# axil_mailbox_sep_wrap: IP-XACT component
VLNV tenstorrent.com:ocah:axil_mailbox_sep_wrap:1.0

## Address spaces and blocks
axil_mailbox_sep_wrap.outbound_mailbox_0: base 'h0, range 'h50, width 64
axil_mailbox_sep_wrap.inbound_mailbox_0: base 'h800, range 'h50, width 64
axil_mailbox_sep_wrap.outbound_mailbox_1: base 'h1000, range 'h50, width 64
axil_mailbox_sep_wrap.inbound_mailbox_1: base 'h1800, range 'h50, width 64
axil_mailbox_sep_wrap.outbound_mailbox_2: base 'h2000, range 'h50, width 64
axil_mailbox_sep_wrap.inbound_mailbox_2: base 'h2800, range 'h50, width 64
axil_mailbox_sep_wrap.outbound_mailbox_3: base 'h3000, range 'h50, width 64
axil_mailbox_sep_wrap.inbound_mailbox_3: base 'h3800, range 'h50, width 64
axil_mailbox_sep_wrap.outbound_mailbox_4: base 'h4000, range 'h50, width 64
axil_mailbox_sep_wrap.inbound_mailbox_4: base 'h4800, range 'h50, width 64
axil_mailbox_sep_wrap.outbound_mailbox_5: base 'h5000, range 'h50, width 64
axil_mailbox_sep_wrap.inbound_mailbox_5: base 'h5800, range 'h50, width 64
axil_mailbox_sep_wrap.outbound_mailbox_6: base 'h6000, range 'h50, width 64
axil_mailbox_sep_wrap.inbound_mailbox_6: base 'h6800, range 'h50, width 64
axil_mailbox_sep_wrap.outbound_mailbox_7: base 'h7000, range 'h50, width 64
axil_mailbox_sep_wrap.inbound_mailbox_7: base 'h7800, range 'h50, width 64

## Registers
Registers are 64-bit, read-only, reset 0x0 unless marked. A register's access mark holds for its fields unless they carry their own. Offsets are from the block's base; lines under a group give offsets from that group; [hi:lo] are bit positions; {n}, {i} and the like mark numbered series; 'fields as' and 'values as' point back to an identical list; <NAME> marks a mode.

## axil_mailbox_sep_wrap.outbound_mailbox_0 — Register interface for a single AXI-Lite mailbox: data FIFOs, level and status flags, and interrupt controls.
Base 0x00000000
Same registers: axil_mailbox_sep_wrap.inbound_mailbox_{n} {0x800+0x1000*n} (n=0..7), axil_mailbox_sep_wrap.outbound_mailbox_1 0x00001000, axil_mailbox_sep_wrap.outbound_mailbox_2 0x00002000, axil_mailbox_sep_wrap.outbound_mailbox_3 0x00003000, axil_mailbox_sep_wrap.outbound_mailbox_4 0x00004000, axil_mailbox_sep_wrap.outbound_mailbox_5 0x00005000, axil_mailbox_sep_wrap.outbound_mailbox_6 0x00006000, axil_mailbox_sep_wrap.outbound_mailbox_7 0x00007000
0x00 WRITE_DATA wo
  [63:0] write_data — Write data to mailbox fifo. Any write pushes one entry, irrespective of WSTRB, including a write with no byte lanes enabled; byte lanes whose strobe is 0 are pushed as 0.
0x08 READ_DATA reset not defined — A read of any size or alignment within this register pops one whole 64-bit entry from the mailbox fifo, and only the byte lanes it requests are returned. A 32-bit read of either half therefore discards the other half of the entry; read this register with 64-bit accesses. A read while the fifo is empty returns 0x0000_0000_FEED_DEAD with an error response.
  [63:0] read_data read-modifies — Read data from mailbox fifo
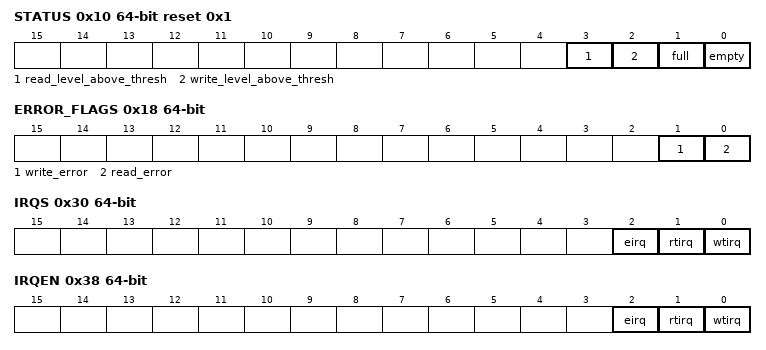
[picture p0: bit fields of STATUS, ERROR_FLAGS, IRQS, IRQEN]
0x10 STATUS reset 0x1
  [3] read_level_above_thresh — If set, read fifo level is higher than threshold set in RIRQT
  [2] write_level_above_thresh — If set, write fifo level is higher than threshold set in WIRQT
  [1] full — 0: Space is available to write, 1: Space is not available to write
  [0] empty — 0: Data is available to read, 1: Data is not available to read
0x18 ERROR_FLAGS — A read of any size or alignment within this register clears every flag in it. The flags are only returned in the lower 32 bits, so a 32-bit read of the upper half returns 0 and still clears them; read this register with 64-bit accesses or at its lower half.
  [1] write_error read-clears — Attempted write to a full mailbox
  [0] read_error read-clears — Attempted read from an empty mailbox
0x20 WIRQT rw
  [63:0] wirqt — When the usage pointer of the FIFO connected to the W channel exceeds this value, a write threshold IRQ is triggered and the corresponding STATUS register bit is set. When a value larger than or equal to the MailboxDepth parameter is written to this register, it gets reduced to MailboxDepth - 1 to ensure an IRQ is triggered when the write FIFO is full.
0x28 RIRQT rw
  [63:0] rirqt — When the fill pointer of the FIFO connected to the R channel exceeds this value, a read threshold IRQ is triggered and the corresponding STATUS register bit is set. When a value larger than or equal to the MailboxDepth parameter is written to this register, it gets reduced to MailboxDepth - 1 to ensure an IRQ is triggered when the read FIFO is full.
0x30 IRQS rw — This register is used to read and clear interrupt requests, regardless of IRQEN register and whether the interrupt is enabled or disabled.
  [2] eirq write-1-clears — On read: [0]: No interrupt request [1]: Error on mailbox access On write: [0]: No acknowledge [1]: Acknowledge and clear interrupt request
  [1] rtirq write-1-clears — On read: [0]: No interrupt request [1]: Usage level threshold in read mailbox exceeded On write: [0]: No acknowledge [1]: Acknowledge and clear interrupt request
  [0] wtirq write-1-clears — On read: [0]: No interrupt request [1]: Usage level threshold in write mailbox exceeded On write: [0]: No acknowledge [1]: Acknowledge and clear interrupt request
0x38 IRQEN rw — This register is used to enable and disable which interrupts are sent to the CPU.
  [2] eirq — [0]: Error IRQ disabled [1]: Error IRQ enabled
  [1] rtirq — [0]: Read threshold IRQ disabled [1]: Read threshold IRQ enabled
  [0] wtirq — [0]: Write threshold IRQ disabled [1]: Write threshold IRQ enabled
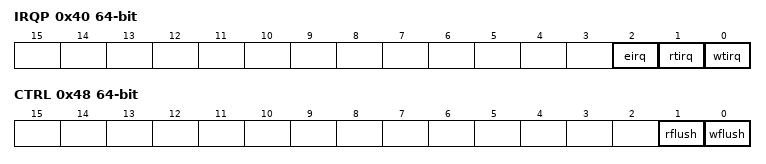
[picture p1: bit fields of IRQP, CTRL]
0x40 IRQP — This register is used to read the current status of the interrupts sent to the CPU.
  [2] eirq — [0]: No error IRQ pending [1]: Error IRQ pending
  [1] rtirq — [0]: No read threshold IRQ pending [1]: Read threshold IRQ pending
  [0] wtirq — [0]: No write threshold IRQ pending [1]: Write threshold IRQ pending
0x48 CTRL wo
  [1] rflush — Flush the read FIFO for this port. The FIFO empties at the end of the cycle in which this write is accepted; a word the peer pushes in that cycle is discarded.
  [0] wflush — Flush the write FIFO for this port. The FIFO empties at the end of the cycle in which this write is accepted.

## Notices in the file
SPDX-License-Identifier: Apache-2.0
SPDX-FileCopyrightText: 2026 Tenstorrent USA, Inc.
